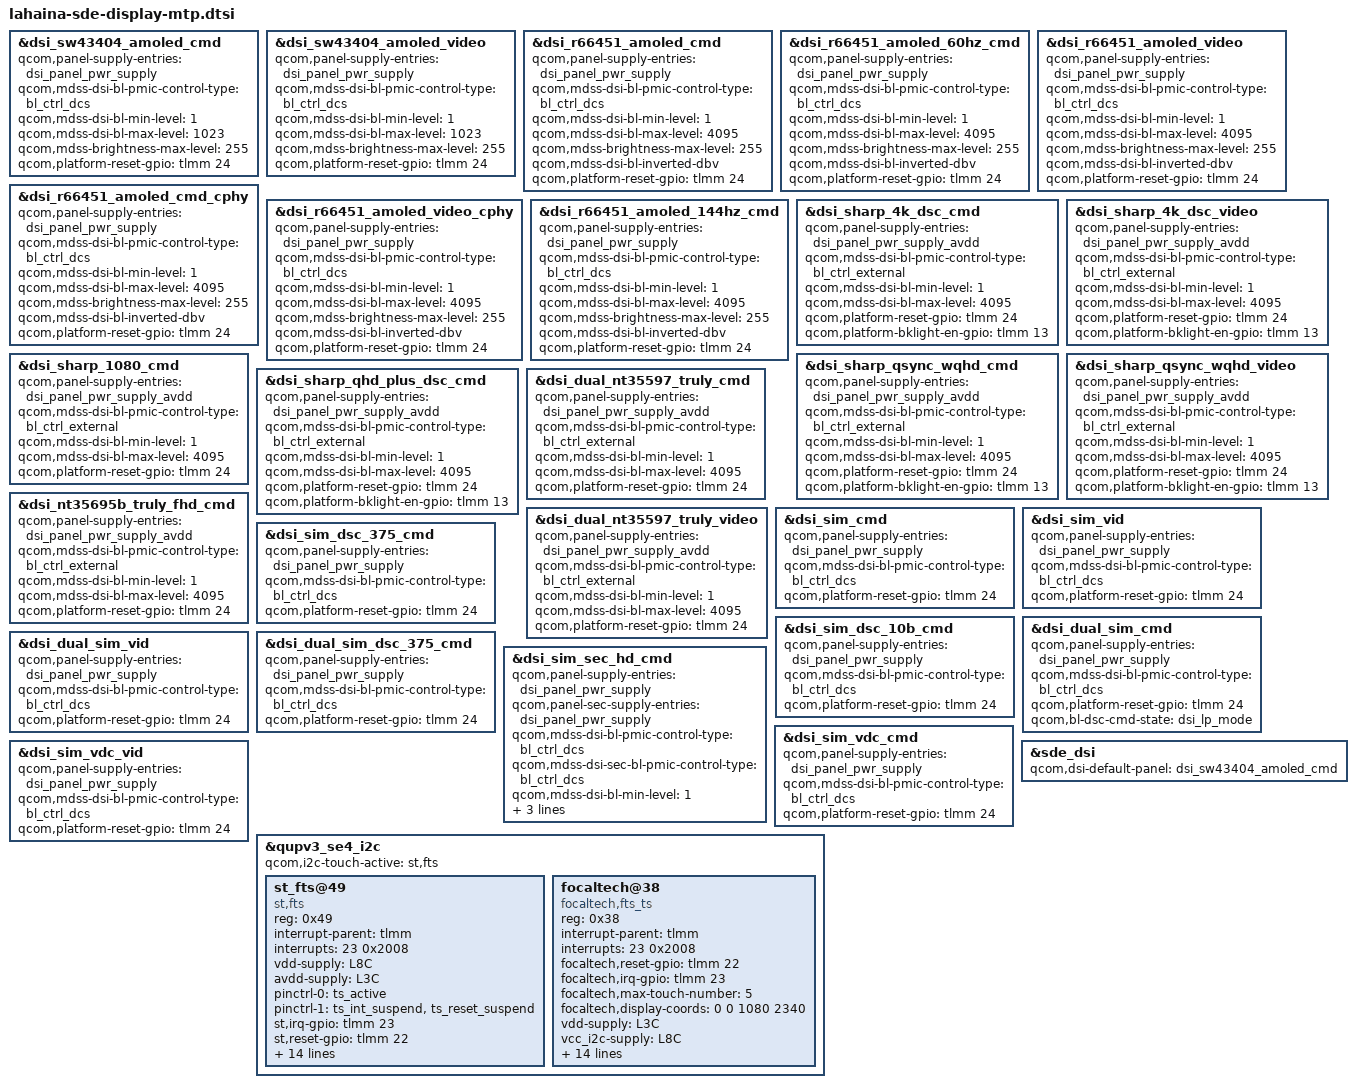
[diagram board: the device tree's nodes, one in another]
// SPDX-License-Identifier: BSD-3-Clause
/*
 * Copyright (c) Qualcomm Technologies, Inc. and/or its subsidiaries.
 */

#include "lahaina-sde-display.dtsi"

&dsi_sw43404_amoled_cmd {
	qcom,panel-supply-entries = <&dsi_panel_pwr_supply>;
	qcom,mdss-dsi-bl-pmic-control-type = "bl_ctrl_dcs";
	qcom,mdss-dsi-bl-min-level = <1>;
	qcom,mdss-dsi-bl-max-level = <1023>;
	qcom,mdss-brightness-max-level = <255>;
	qcom,platform-reset-gpio = <&tlmm 24 0>;
};

&dsi_sw43404_amoled_video {
	qcom,panel-supply-entries = <&dsi_panel_pwr_supply>;
	qcom,mdss-dsi-bl-pmic-control-type = "bl_ctrl_dcs";
	qcom,mdss-dsi-bl-min-level = <1>;
	qcom,mdss-dsi-bl-max-level = <1023>;
	qcom,mdss-brightness-max-level = <255>;
	qcom,platform-reset-gpio = <&tlmm 24 0>;
};

&dsi_r66451_amoled_cmd {
	qcom,panel-supply-entries = <&dsi_panel_pwr_supply>;
	qcom,mdss-dsi-bl-pmic-control-type = "bl_ctrl_dcs";
	qcom,mdss-dsi-bl-min-level = <1>;
	qcom,mdss-dsi-bl-max-level = <4095>;
	qcom,mdss-brightness-max-level = <255>;
	qcom,mdss-dsi-bl-inverted-dbv;
	qcom,platform-reset-gpio = <&tlmm 24 0>;
};

&dsi_r66451_amoled_60hz_cmd {
	qcom,panel-supply-entries = <&dsi_panel_pwr_supply>;
	qcom,mdss-dsi-bl-pmic-control-type = "bl_ctrl_dcs";
	qcom,mdss-dsi-bl-min-level = <1>;
	qcom,mdss-dsi-bl-max-level = <4095>;
	qcom,mdss-brightness-max-level = <255>;
	qcom,mdss-dsi-bl-inverted-dbv;
	qcom,platform-reset-gpio = <&tlmm 24 0>;
};

&dsi_r66451_amoled_video {
	qcom,panel-supply-entries = <&dsi_panel_pwr_supply>;
	qcom,mdss-dsi-bl-pmic-control-type = "bl_ctrl_dcs";
	qcom,mdss-dsi-bl-min-level = <1>;
	qcom,mdss-dsi-bl-max-level = <4095>;
	qcom,mdss-brightness-max-level = <255>;
	qcom,mdss-dsi-bl-inverted-dbv;
	qcom,platform-reset-gpio = <&tlmm 24 0>;
};

&dsi_r66451_amoled_cmd_cphy {
	qcom,panel-supply-entries = <&dsi_panel_pwr_supply>;
	qcom,mdss-dsi-bl-pmic-control-type = "bl_ctrl_dcs";
	qcom,mdss-dsi-bl-min-level = <1>;
	qcom,mdss-dsi-bl-max-level = <4095>;
	qcom,mdss-brightness-max-level = <255>;
	qcom,mdss-dsi-bl-inverted-dbv;
	qcom,platform-reset-gpio = <&tlmm 24 0>;
};

&dsi_r66451_amoled_video_cphy {
	qcom,panel-supply-entries = <&dsi_panel_pwr_supply>;
	qcom,mdss-dsi-bl-pmic-control-type = "bl_ctrl_dcs";
	qcom,mdss-dsi-bl-min-level = <1>;
	qcom,mdss-dsi-bl-max-level = <4095>;
	qcom,mdss-brightness-max-level = <255>;
	qcom,mdss-dsi-bl-inverted-dbv;
	qcom,platform-reset-gpio = <&tlmm 24 0>;
};

&dsi_r66451_amoled_144hz_cmd {
	qcom,panel-supply-entries = <&dsi_panel_pwr_supply>;
	qcom,mdss-dsi-bl-pmic-control-type = "bl_ctrl_dcs";
	qcom,mdss-dsi-bl-min-level = <1>;
	qcom,mdss-dsi-bl-max-level = <4095>;
	qcom,mdss-brightness-max-level = <255>;
	qcom,mdss-dsi-bl-inverted-dbv;
	qcom,platform-reset-gpio = <&tlmm 24 0>;
};

&dsi_sharp_4k_dsc_cmd {
	qcom,panel-supply-entries = <&dsi_panel_pwr_supply_avdd>;
	qcom,mdss-dsi-bl-pmic-control-type = "bl_ctrl_external";
	qcom,mdss-dsi-bl-min-level = <1>;
	qcom,mdss-dsi-bl-max-level = <4095>;
	qcom,platform-reset-gpio = <&tlmm 24 0>;
	qcom,platform-bklight-en-gpio = <&tlmm 13 0>;
};

&dsi_sharp_4k_dsc_video {
	qcom,panel-supply-entries = <&dsi_panel_pwr_supply_avdd>;
	qcom,mdss-dsi-bl-pmic-control-type = "bl_ctrl_external";
	qcom,mdss-dsi-bl-min-level = <1>;
	qcom,mdss-dsi-bl-max-level = <4095>;
	qcom,platform-reset-gpio = <&tlmm 24 0>;
	qcom,platform-bklight-en-gpio = <&tlmm 13 0>;
};

&dsi_sharp_1080_cmd {
	qcom,panel-supply-entries = <&dsi_panel_pwr_supply_avdd>;
	qcom,mdss-dsi-bl-pmic-control-type = "bl_ctrl_external";
	qcom,mdss-dsi-bl-min-level = <1>;
	qcom,mdss-dsi-bl-max-level = <4095>;
	qcom,platform-reset-gpio = <&tlmm 24 0>;
};

&dsi_sharp_qsync_wqhd_cmd {
	qcom,panel-supply-entries = <&dsi_panel_pwr_supply_avdd>;
	qcom,mdss-dsi-bl-pmic-control-type = "bl_ctrl_external";
	qcom,mdss-dsi-bl-min-level = <1>;
	qcom,mdss-dsi-bl-max-level = <4095>;
	qcom,platform-reset-gpio = <&tlmm 24 0>;
	qcom,platform-bklight-en-gpio = <&tlmm 13 0>;
};

&dsi_sharp_qsync_wqhd_video {
	qcom,panel-supply-entries = <&dsi_panel_pwr_supply_avdd>;
	qcom,mdss-dsi-bl-pmic-control-type = "bl_ctrl_external";
	qcom,mdss-dsi-bl-min-level = <1>;
	qcom,mdss-dsi-bl-max-level = <4095>;
	qcom,platform-reset-gpio = <&tlmm 24 0>;
	qcom,platform-bklight-en-gpio = <&tlmm 13 0>;
};

&dsi_sharp_qhd_plus_dsc_cmd {
	qcom,panel-supply-entries = <&dsi_panel_pwr_supply_avdd>;
	qcom,mdss-dsi-bl-pmic-control-type = "bl_ctrl_external";
	qcom,mdss-dsi-bl-min-level = <1>;
	qcom,mdss-dsi-bl-max-level = <4095>;
	qcom,platform-reset-gpio = <&tlmm 24 0>;
	qcom,platform-bklight-en-gpio = <&tlmm 13 0>;
};

&dsi_dual_nt35597_truly_cmd {
	qcom,panel-supply-entries = <&dsi_panel_pwr_supply_avdd>;
	qcom,mdss-dsi-bl-pmic-control-type = "bl_ctrl_external";
	qcom,mdss-dsi-bl-min-level = <1>;
	qcom,mdss-dsi-bl-max-level = <4095>;
	qcom,platform-reset-gpio = <&tlmm 24 0>;
};

&dsi_dual_nt35597_truly_video {
	qcom,panel-supply-entries = <&dsi_panel_pwr_supply_avdd>;
	qcom,mdss-dsi-bl-pmic-control-type = "bl_ctrl_external";
	qcom,mdss-dsi-bl-min-level = <1>;
	qcom,mdss-dsi-bl-max-level = <4095>;
	qcom,platform-reset-gpio = <&tlmm 24 0>;
};

&dsi_nt35695b_truly_fhd_cmd {
	qcom,panel-supply-entries = <&dsi_panel_pwr_supply_avdd>;
	qcom,mdss-dsi-bl-pmic-control-type = "bl_ctrl_external";
	qcom,mdss-dsi-bl-min-level = <1>;
	qcom,mdss-dsi-bl-max-level = <4095>;
	qcom,platform-reset-gpio = <&tlmm 24 0>;
};

&dsi_sim_cmd {
	qcom,panel-supply-entries = <&dsi_panel_pwr_supply>;
	qcom,mdss-dsi-bl-pmic-control-type = "bl_ctrl_dcs";
	qcom,platform-reset-gpio = <&tlmm 24 0>;
};

&dsi_sim_vid {
	qcom,panel-supply-entries = <&dsi_panel_pwr_supply>;
	qcom,mdss-dsi-bl-pmic-control-type = "bl_ctrl_dcs";
	qcom,platform-reset-gpio = <&tlmm 24 0>;
};

&dsi_sim_dsc_375_cmd {
	qcom,panel-supply-entries = <&dsi_panel_pwr_supply>;
	qcom,mdss-dsi-bl-pmic-control-type = "bl_ctrl_dcs";
	qcom,platform-reset-gpio = <&tlmm 24 0>;
};

&dsi_sim_dsc_10b_cmd {
	qcom,panel-supply-entries = <&dsi_panel_pwr_supply>;
	qcom,mdss-dsi-bl-pmic-control-type = "bl_ctrl_dcs";
	qcom,platform-reset-gpio = <&tlmm 24 0>;
};

&dsi_dual_sim_cmd {
	qcom,panel-supply-entries = <&dsi_panel_pwr_supply>;
	qcom,mdss-dsi-bl-pmic-control-type = "bl_ctrl_dcs";
	qcom,platform-reset-gpio = <&tlmm 24 0>;
	qcom,bl-dsc-cmd-state = "dsi_lp_mode";
};

&dsi_dual_sim_vid {
	qcom,panel-supply-entries = <&dsi_panel_pwr_supply>;
	qcom,mdss-dsi-bl-pmic-control-type = "bl_ctrl_dcs";
	qcom,platform-reset-gpio = <&tlmm 24 0>;
};

&dsi_dual_sim_dsc_375_cmd {
	qcom,panel-supply-entries = <&dsi_panel_pwr_supply>;
	qcom,mdss-dsi-bl-pmic-control-type = "bl_ctrl_dcs";
	qcom,platform-reset-gpio = <&tlmm 24 0>;
};

&dsi_sim_sec_hd_cmd {
	qcom,panel-supply-entries = <&dsi_panel_pwr_supply>;
	qcom,panel-sec-supply-entries = <&dsi_panel_pwr_supply>;
	qcom,mdss-dsi-bl-pmic-control-type = "bl_ctrl_dcs";
	qcom,mdss-dsi-sec-bl-pmic-control-type = "bl_ctrl_dcs";
	qcom,mdss-dsi-bl-min-level = <1>;
	qcom,mdss-dsi-bl-max-level = <1023>;
	qcom,platform-reset-gpio = <&tlmm 24 0>;
	qcom,platform-sec-reset-gpio = <&tlmm 25 0>;
};

&dsi_sim_vdc_cmd {
	qcom,panel-supply-entries = <&dsi_panel_pwr_supply>;
	qcom,mdss-dsi-bl-pmic-control-type = "bl_ctrl_dcs";
	qcom,platform-reset-gpio = <&tlmm 24 0>;
};

&dsi_sim_vdc_vid {
	qcom,panel-supply-entries = <&dsi_panel_pwr_supply>;
	qcom,mdss-dsi-bl-pmic-control-type = "bl_ctrl_dcs";
	qcom,platform-reset-gpio = <&tlmm 24 0>;
};

&sde_dsi {
	qcom,dsi-default-panel = <&dsi_sw43404_amoled_cmd>;
};

&qupv3_se4_i2c {
	#address-cells = <1>;
	#size-cells = <0>;

	status = "ok";
	qcom,i2c-touch-active = "st,fts";

	st_fts@49 {
		compatible = "st,fts";
		reg = <0x49>;
		interrupt-parent = <&tlmm>;
		interrupts = <23 0x2008>;
		vdd-supply = <&L8C>;
		avdd-supply = <&L3C>;
		pinctrl-names = "pmx_ts_active", "pmx_ts_suspend";
		pinctrl-0 = <&ts_active>;
		pinctrl-1 = <&ts_int_suspend &ts_reset_suspend>;
		st,irq-gpio = <&tlmm 23 0x2008>;
		st,reset-gpio = <&tlmm 22 0x00>;
		st,x-flip = <1>;
		st,y-flip = <1>;
		st,regulator_dvdd = "vdd";
		st,regulator_avdd = "avdd";
		st,trusted-touch-mode = "vm_mode";
		st,touch-environment = "pvm";
		st,trusted-touch-spi-irq = <566>;
		st,trusted-touch-io-bases = <0xF114000 0xF115000 0xF116000 0xF117000 0x990000 0x00910000>;
		st,trusted-touch-io-sizes = <0x1000 0x1000 0x1000 0x1000 0x1000 0x4000>;
		panel = <&dsi_sw43404_amoled_cmd &dsi_sw43404_amoled_video
			 &dsi_sw43404_amoled_fhd_plus_cmd>;
	};

	focaltech@38 {
		compatible = "focaltech,fts_ts";
		reg = <0x38>;
		interrupt-parent = <&tlmm>;
		interrupts = <23 0x2008>;
		focaltech,reset-gpio = <&tlmm 22 0x00>;
		focaltech,irq-gpio = <&tlmm 23 0x2008>;
		focaltech,max-touch-number = <5>;
		focaltech,display-coords = <0 0 1080 2340>;

		vdd-supply = <&L3C>;
		vcc_i2c-supply = <&L8C>;

		pinctrl-names = "pmx_ts_active", "pmx_ts_suspend","pmx_ts_release";
		pinctrl-0 = <&ts_active>;
		pinctrl-1 = <&ts_int_suspend &ts_reset_suspend>;
		pinctrl-2 = <&ts_release>;

		panel = <&dsi_r66451_amoled_cmd
			 &dsi_r66451_amoled_60hz_cmd
			 &dsi_r66451_amoled_video &dsi_r66451_amoled_144hz_cmd>;

		focaltech,trusted-touch-mode = "vm_mode";
		focaltech,touch-environment = "pvm";
		focaltech,trusted-touch-spi-irq = <566>;
		focaltech,trusted-touch-io-bases = <0xF114000 0xF115000 0xF116000 0xF117000 0x990000 0x00910000>;
		focaltech,trusted-touch-io-sizes = <0x1000 0x1000 0x1000 0x1000 0x1000 0x4000>;
	};
};
